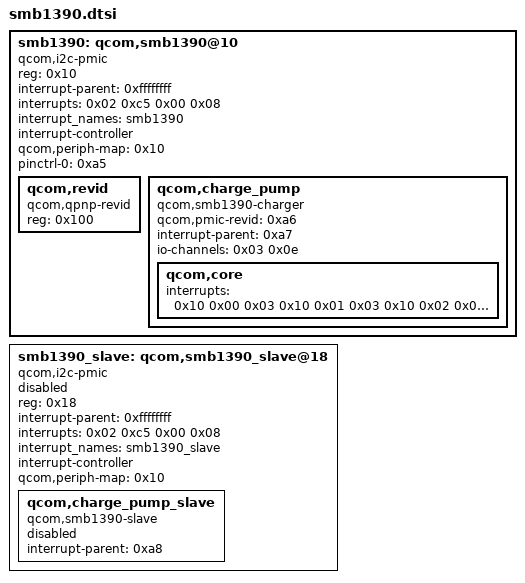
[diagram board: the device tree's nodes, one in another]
/* Copyright (c) 2018, The Linux Foundation. All rights reserved.
 *
 * This program is free software; you can redistribute it and/or modify
 * it under the terms of the GNU General Public License version 2 and
 * only version 2 as published by the Free Software Foundation.
 *
 * This program is distributed in the hope that it will be useful,
 * but WITHOUT ANY WARRANTY; without even the implied warranty of
 * MERCHANTABILITY or FITNESS FOR A PARTICULAR PURPOSE.  See the
 * GNU General Public License for more details.
 */

#include <dt-bindings/interrupt-controller/irq.h>

smb1390: qcom,smb1390@10 {
				compatible = "qcom,i2c-pmic";
				reg = <0x10>;
				#address-cells = <0x01>;
				#size-cells = <0x00>;
				interrupt-parent = <0xffffffff>;
				interrupts = <0x02 0xc5 0x00 0x08>;
				interrupt_names = "smb1390";
				interrupt-controller;
				#interrupt-cells = <0x03>;
				qcom,periph-map = <0x10>;
				status = "ok";
				pinctrl-names = "default";
				pinctrl-0 = <0xa5>;
				phandle = <0xa7>;

				qcom,revid {
					compatible = "qcom,qpnp-revid";
					reg = <0x100>;
					phandle = <0xa6>;
				};

				qcom,charge_pump {
					compatible = "qcom,smb1390-charger";
					qcom,pmic-revid = <0xa6>;
					interrupt-parent = <0xa7>;
					status = "ok";
					io-channels = <0x03 0x0e>;
					io-channel-names = "cp_die_temp";
					phandle = <0x121>;

					qcom,core {
						interrupts = <0x10 0x00 0x03 0x10 0x01 0x03 0x10 0x02 0x03 0x10 0x03 0x03 0x10 0x04 0x03 0x10 0x05 0x01 0x10 0x06 0x01 0x10 0x07 0x01>;
						interrupt-names = "switcher-off-window\0switcher-off-fault\0tsd-fault\0irev-fault\0vph-ov-hard\0vph-ov-soft\0ilim\0temp-alarm";
					};
				};
			};

smb1390_slave: qcom,smb1390_slave@18 {
				compatible = "qcom,i2c-pmic";
				reg = <0x18>;
				#address-cells = <0x01>;
				#size-cells = <0x00>;
				interrupt-parent = <0xffffffff>;
				interrupts = <0x02 0xc5 0x00 0x08>;
				interrupt_names = "smb1390_slave";
				interrupt-controller;
				#interrupt-cells = <0x03>;
				qcom,periph-map = <0x10>;
				status = "disabled";
				phandle = <0xa8>;

				qcom,charge_pump_slave {
					compatible = "qcom,smb1390-slave";
					interrupt-parent = <0xa8>;
					status = "disabled";
					phandle = <0x122>;
				};
			};
